# IND83212 register map
Series: Verne; File version: B0
CPU: CM0 r0p1, selectable endian, no MPU, no FPU, 4 interrupt priority bits
Registers are 32-bit, read-write, no defined reset value unless marked. A register's access mark holds for its fields unless they carry their own. Offsets are from the block's base; [hi:lo] are bit positions.

## IOCTRLA — I/O configuration and DFT pin control
Base 0x50011000; register names take the prefix IOCTRLA_
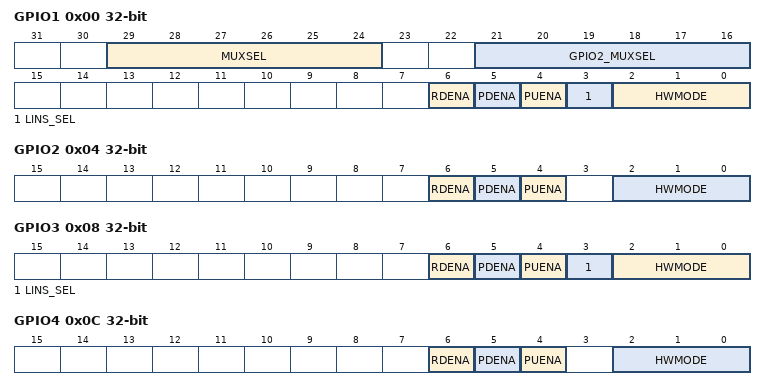
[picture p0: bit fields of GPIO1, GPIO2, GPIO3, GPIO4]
0x00 GPIO1 — GPIO Pin 1 Control
  [29:24] MUXSEL — GPIO1_MUXSEL:Selects debug signal to be output on gpio1. 0x0: PMUA (Power Management Unit Asic) QACK 0x1: PMUA (Power Management Unit Asic) Wakeup signal 0x2: PMUA (Power Management Unit Asic) snowflake 0x3: LIN Slave Output of 1st Stage Glitch Filter 0x4: LIN Slave Output of 2nd Stage Glitch Filter 0x5: LIN Slave Output of 3rd Stage Glitch Filter 0x6: LIN Slave PHY Output Rxd 0x7: LIN Slave PHY Input Txd 0x8: CRGA (Clock Reset Generation Asic) (scan_test_mode | lf_rc_clk) 0x9: CRGA (Clock Reset Generation Asic) (scan_test_mode | hf_rc_clk) 0xa: CRGA (Clock Reset Generation Asic) (scan_test_mode | lf_rc_sts) 0xb: CRGA (Clock Reset Generation Asic) (scan_test_mode | hf_rc_sts) 0xc: CRGA (Clock Reset Generation Asic) (scan_test_mode | clk_sys_gated) 0xd: CRGA (Clock Reset Generation Asic) (a_por_n) 0xe: CRGA (Clock Reset Generation Asic) (bor_3v3_n) 0xf: CRGA (Clock Reset Generation Asic) (ovtemp_flag) 0x10: CRGA (Clock Reset Generation Asic) (bor_1v5_n) 0x11: CRGA (Clock Reset Generation Asic) (wdt_bark) 0x12: ADC controller clk adc_clk_in 0x22: LIN Slave Input of Core rxd 0x23: LIN Slave Output of Core txd 0x24: BOR CONTROL STATE MACHINE state[0] 0x25: BOR CONTROL STATE MACHINE state[1] 0x26: BOR CONTROL STATE MACHINE bor_bias_ena 0x27: BOR CONTROL STATE MACHINE bor_bias_ena_l 0x28: BOR CONTROL STATE MACHINE pmua_bor_bias_ena 0x29: BOR CONTROL STATE MACHINE hf_clk_allowed 0x2a: BOR CONTROL STATE MACHINE hf_active 0x2b: BOR CONTROL STATE MACHINE pmua_bor_arm_sync 0x2c: BATTERY VOLTAGE MONITOR vbat_low 0x2d: BATTERY VOLTAGE MONITOR vbat_high 0x2e: BATTERY VOLTAGE MONITOR vbat_low_flag 0x2f: BATTERY VOLTAGE MONITOR vbat_high_flag 0x30: BATTERY VOLTAGE MONITOR vbat_low_dbnc 0x31: BATTERY VOLTAGE MONITOR vbat_high_dbnc
  [21:16] GPIO2_MUXSEL — Selects debug signal to be output on gpio2. Refer to GPIO1_MUXSEL for signal selection
  [6] RDENA — read enable. 0x0: Disable Read path on the GPIO 0x1: Enable Read path on the GPIO
  [5] PDENA — pulldown enable. 0x0: Disable 100K Ohm Pull Down 0x1: Enable 100K Ohm Pull Down
  [4] PUENA — pullup enable (active-low). 0x0: Enable 100K Ohm Pull Up 0x1: Disable 100K Ohm Pull Up
  [3] LINS_SEL — LINS Connection Select. 0x0: LINS RXD External input Mode. 0x1: Single wire mode, LINS RXD/LINS TXD, Open-drain output.
  [2:0] HWMODE — hardware mode. 0x0: GPIO Mode. 'GPIO Barium' reads and writes data to the GPIO. Output Enable is controlled by GPIO Barium via the direction bit. Read Enable, Pull-Up, and Pull-Down are controlled by GPIO register in IOCTRLA. 0x1: PWM Mode. 'PWM Barium' writes data to the GPIO. 0x2: Testmux Mode. 'Digital Testmux' writes data to the GPIO. DEBUG Access must be enabled in the system control block to allow testmux outputs. 0x3: GPIO1_LINS_SEL=0 : LINS RXD; GPIO1_LINS_SEL=1 : Single wire mode, LINS RXD/LINS TXD, Open-drain output. 0x4: Monitor 1st Stage input of LINS RX Glitch filter. 0x5: Monitor 1st Stage output of LINS RX Glitch filter. 0x6: Monitor 2nd Stage output of LINS RX Glitch filter. 0x7: Monitor 3rd Stage output of LINS RX Glitch filter.
0x04 GPIO2 — GPIO Pin 2 Control
  [6] RDENA — read enable. 0x0: Disable Read path on the GPIO 0x1: Enable Read path on the GPIO
  [5] PDENA — pulldown enable. 0x0: Disable 100K Ohm Pull Down 0x1: Enable 100K Ohm Pull Down
  [4] PUENA — pullup enable (active-low). 0x0: Enable 100K Ohm Pull Up 0x1: Disable 100K Ohm Pull Up
  [2:0] HWMODE — hardware mode. 0x0: GPIO Mode. 'GPIO Barium' reads and writes data to the GPIO. Output Enable is controlled by GPIO Barium via the direction bit. Read Enable, Pull-Up, and Pull-Down are controlled by GPIO register in IOCTRLA. 0x1: PWM Mode. 'PWM Barium' writes data to the GPIO. 0x2: LINS PHY TXD Drive Mode. GPIO input connects to LINS PHY TXD. DEBUG Access must be enabled in the system control block to drive LINS PHY TXD outputs. 0x3: LINS Core TXD Monitor. 0x4: Testmux Mode. 'Digital Testmux' writes data to the GPIO. DEBUG Access must be enabled in the system control block to allow testmux outputs. 0x5: Monitor 1st Stage output of LINS RX Glitch filter. 0x6: Monitor 2nd Stage output of LINS RX Glitch filter. 0x7: Monitor 3rd Stage output of LINS RX Glitch filter.
0x08 GPIO3 — GPIO Pin 3 Control
  [6] RDENA — read enable. 0x0: Disable Read path on the GPIO 0x1: Enable Read path on the GPIO
  [5] PDENA — pulldown enable. 0x0: Disable 100K Ohm Pull Down 0x1: Enable 100K Ohm Pull Down
  [4] PUENA — pullup enable (active-low). 0x0: Enable 100K Ohm Pull Up 0x1: Disable 100K Ohm Pull Up
  [3] LINS_SEL — LINS Connection Select. 0x0: LINS RXD External input Mode. 0x1: Single wire mode, LINS RXD/LINS TXD, Open-drain output.
  [2:0] HWMODE — hardware mode. 0x0: GPIO Mode. 'GPIO Barium' reads and writes data to the GPIO. Output Enable is controlled by GPIO Barium via the direction bit. Read Enable, Pull-Up, and Pull-Down are controlled by GPIO register in IOCTRLA. 0x1: PWM Mode. 'PWM Barium' writes data to the GPIO. 0x2: LINS RXD which is input of lins_core connects to GPIO output. 0x3: LINS_SEL=0 : LINS RXD; LINS_SEL=1 : Single wire mode, LINS RXD/LINS TXD, Open-drain output. 0x4: Monitor 1st Stage input of LINS RX Glitch filter. 0x5: Monitor 1st Stage output of LINS RX Glitch filter. 0x6: Monitor 2nd Stage output of LINS RX Glitch filter. 0x7: Monitor 3rd Stage output of LINS RX Glitch filter.
0x0C GPIO4 — GPIO Pin 4 Control
  [6] RDENA — read enable. 0x0: Disable Read path on the GPIO 0x1: Enable Read path on the GPIO
  [5] PDENA — pulldown enable. 0x0: Disable 100K Ohm Pull Down 0x1: Enable 100K Ohm Pull Down
  [4] PUENA — pullup enable (active-low). 0x0: Enable 100K Ohm Pull Up 0x1: Disable 100K Ohm Pull Up
  [2:0] HWMODE — hardware mode. 0x0: GPIO Mode. 'GPIO Barium' reads and writes data to the GPIO. Output Enable is controlled by GPIO Barium via the direction bit. Read Enable, Pull-Up, and Pull-Down are controlled by GPIO register in IOCTRLA. 0x1: PWM Mode. 'PWM Barium' writes data to the GPIO. 0x2: Testmux Mode. GPIO input connects to LINS TXD. 0x3: LINS CORE TXD Monitor 0x4: Monitor 1st Stage input of LINS RX Glitch filter. 0x5: Monitor 1st Stage output of LINS RX Glitch filter. 0x6: Monitor 2nd Stage output of LINS RX Glitch filter. 0x7: Monitor 3rd Stage output of LINS RX Glitch filter.
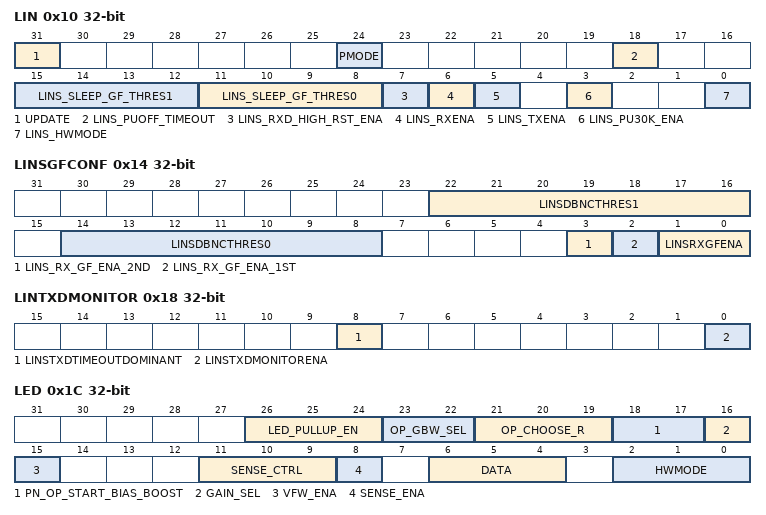
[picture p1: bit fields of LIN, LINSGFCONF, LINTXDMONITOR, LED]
0x10 LIN — LIN Pin Control
  [31] UPDATE dual — LIN Configure Update. Set to update the Configurations to PRE5V domains. NOTE: DO NOT change the CTRL register when it is high, which indicates there is an update in progress, It gets cleared by the core when the current update is done
  [24] PMODE — LIN Power Mode. Control LINS power state in hibernate mode. 0x0: Regardless of the related enable bits, LIN TX analog parts will be shut-down in hibernate mode, unless any LIN dominant signal is detected. 0x1: LIN TX analog parts are still controlled by theirs corresponding enable bits.
  [18] LINS_PUOFF_TIMEOUT — LINS Pullup Disable in dominant TimeOut condition. Set to disable LINS 30K pullup in case that lin bus is shorted to ground(Bus idle dominant timeout is detected) for saving power. LINS Pullup will be recovered automatically if bus idle dominant timeout is released by any bus activity. Only reset by power-on sequence. NOTE: The write operation of this register takes effect by PMUA_SFRS->CTRL.UPDATE
  [15:12] LINS_SLEEP_GF_THRES1 — LINS RXD glitch filter threshold for 0 to 1, detect '1' width of (T_clk_lf*resetvalue = 4us*3 = 12[us], NOTE: The write operation of this register takes effect by configuring SYSCTRLA_SFRS->TRIM_ACCESS_KEY.TRIM_ACCESS_KEY, FILT_ACCESS.FILT_UNLOCK and IOCTRLA_SFRS->LIN.UPDATE
  [11:8] LINS_SLEEP_GF_THRES0 — LINS RXD glitch filter threshold for 1 to 0, detect '0' width of (T_clk_lf*resetvalue = 4us*3 = 12[us], NOTE: The write operation of this register takes effect by configuring SYSCTRLA_SFRS->TRIM_ACCESS_KEY.TRIM_ACCESS_KEY, FILT_ACCESS.FILT_UNLOCK and IOCTRLA_SFRS->LIN.UPDATE
  [7] LINS_RXD_HIGH_RST_ENA — Enable signal that LINs RXD glitch filter at sleep mode is asynchronous reset by high of LINs_RXD. NOTE: The write operation of this register takes effect by configuring SYSCTRLA_SFRS->TRIM_ACCESS_KEY.TRIM_ACCESS_KEY, FILT_ACCESS.FILT_UNLOCK and IOCTRLA_SFRS->LIN.UPDATE
  [6] LINS_RXENA — LIN receive enable. NOTE: The write operation of this register takes effect by IOCTRLA_SFRS->LIN.UPDATE
  [5] LINS_TXENA — LIN transmit enable.
  [3] LINS_PU30K_ENA — LIN 30K pullup enable.
  [0] LINS_HWMODE — LIN Slave hardware mode. 0x0: Hardware Mode Disabled. GPIO2 writes/reads the LIN I/O pin. 0x1: Hardware Mode Enabled. LIN peripheral writes/reads the LIN I/O pin.
0x14 LINSGFCONF — LINS Glitch Filter Configuration in active mode
  [22:16] LINSDBNCTHRES1 — 3rd Stage LINS Debounce Threshold for 0 to 1. 3rd Stage LINS Debounce Threshold for 0 to 1, detect '1' width of (T_clksys*resetvalue = 62.5ns*40 = 2.5[us]. NOTE: The write operation of this register takes effect by configuring SYSCTRLA_SFRS->TRIM_ACCESS_KEY.TRIM_ACCESS_KEY, FILT_ACCESS.FILT_UNLOCK
  [14:8] LINSDBNCTHRES0 — 3rd Stage LINS Debounce Threshold for 1 to 0. 3rd Stage LINS Debounce Threshold for 1 to 0, detect '0' width of (T_clksys*resetvalue = 62.5ns*40 = 2.5[us]. NOTE: The write operation of this register takes effect by configuring SYSCTRLA_SFRS->TRIM_ACCESS_KEY.TRIM_ACCESS_KEY, FILT_ACCESS.FILT_UNLOCK
  [3] LINS_RX_GF_ENA_2ND — LINS RXD 2nd Glitch Filter enables. Enable LINS Glitch Filter 2nd stage. NOTE: The write operation of this register takes effect by configuring SYSCTRLA_SFRS->TRIM_ACCESS_KEY.TRIM_ACCESS_KEY, FILT_ACCESS.FILT_UNLOCK
  [2] LINS_RX_GF_ENA_1ST — LINS RXD 1st Glitch Filter enables. Enable LINS Glitch Filter 1st stage. NOTE: The write operation of this register takes effect by configuring SYSCTRLA_SFRS->TRIM_ACCESS_KEY.TRIM_ACCESS_KEY, FILT_ACCESS.FILT_UNLOCK
  [1:0] LINSRXGFENA — LINS RXD Glitch Filter enables. Bit0: Enable LINS Glitch Filter 3rd stage; Bit1: Enable LINS Glitch Filter for Sleep Mode. NOTE: The write operation of this register takes effect by configuring SYSCTRLA_SFRS->TRIM_ACCESS_KEY.TRIM_ACCESS_KEY, FILT_ACCESS.FILT_UNLOCK
0x18 LINTXDMONITOR — LIN TXD Dominant Timeout
  [8] LINSTXDTIMEOUTDOMINANT ro — Tx Dominant Timeout. The bit is set by LINS TxD monitor if LINS's TxD is stuck at dominant output for 64ms. A dominant to recessive transition of the TxD will clear this bit. LIN's TX will be disabled automatically when this bit is set.
  [0] LINSTXDMONITORENA — LINS TxD Monitor enable.
0x1C LED — LED Pin Control
  [26:24] LED_PULLUP_EN — LED PULLUP ENABLE. LED PAD Pullup enable, ONE HOT code. 0x1: LED0 PAD pullup to PRE5V through a diode and a 50K resistor 0x2: LED1 PAD pullup to PRE5V through a diode and a 50K resistor 0x4: LED2 PAD pullup to PRE5V through a diode and a 50K resistor
  [23:22] OP_GBW_SEL — LED SENSE OP GBW SEL. PN detect fully differential Op GBW choose 00: 3M 01: 5M 10: 8M 11: 10M
  [21:19] OP_CHOOSE_R — LED SENSE OP CHOOSE R. choose nulling resistor to do frequency compensation. Which denpends on the bandwidth of the OP. R<2:0> R GBW<1:0>(CL=3pF) 000 0.5K 11(10M) 001 2.5K 10(8M) 01(5M) 010 4.5K 011 6.5K 11(3M) 100 8.5K 101 10.5K 110 12.5K 111 14.5K
  [18:17] PN_OP_START_BIAS_BOOST — PN OP START BIAS BOOST. PN diff OP start bias current 00: 250nA 01: 500nA 10: 750nA 11: 1uA
  [16] GAIN_SEL — LED Sense AFE gain select. V_ADC = (vbat-vled)*GAIN , where V_ADC is voltage to ADC LED channle, and GAIN is selected by GAIN_SEL as following: 0x0: GAIN = 0.533 0x1: GAIN = 0.533/2
  [15] VFW_ENA — LED Forward Voltage Current Enable. Set to enable the independent LED VFW current source(maximum=5mA). When ADC CH2 measurement is active, the LED channel selected by CH2_SEL will be driven by LED_VFW current source.
  [11:9] SENSE_CTRL — LED. LED Sense Control bits for override control/debug.
  [8] SENSE_ENA — LED Forward Voltage Sense Enable. Set to enable LED forward voltage sense module. After setting this bit, it's recommended to wait ~40us before ADC conversion for LED_SENSE to settle down.
  [6:4] DATA — LED Data Out. When the LED hardware mode is disabled, then the data in this register bit is used to drive the LED driver. Each bit controls the corresonding LED Channel respectively.
  [2:0] HWMODE — LED hardware mode. LED Hardware Mode Enable. Each bit controls the corresponding LED Channel respectively. 0x0: Hardware Mode Disabled. LED_DATA register drives the LED Data Output pin. Read is not available on this pin. 0x1: Hardware Mode Enabled. PWM_BARIUM peripheral drives the LED Data Output pin. Read is not available on this pin.
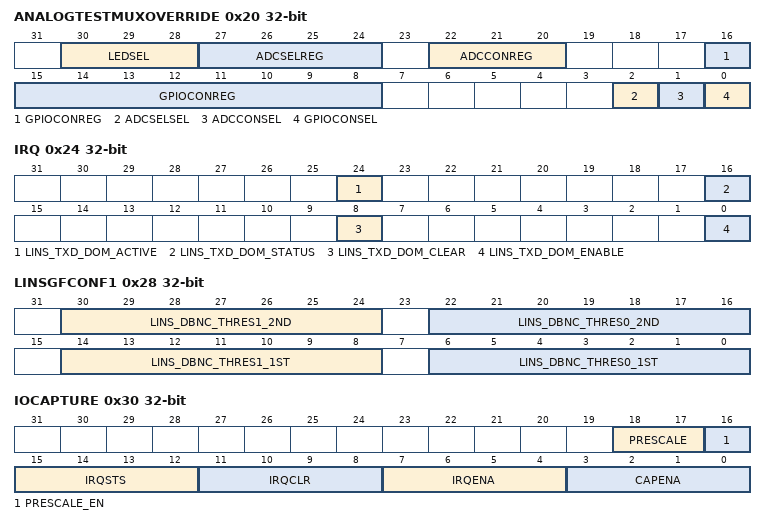
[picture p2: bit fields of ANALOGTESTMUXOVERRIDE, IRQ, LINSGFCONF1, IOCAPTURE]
0x20 ANALOGTESTMUXOVERRIDE — Analog Testmux Override.This register controls the multiplexers for analog signals. The select bit allows firmware to control the corresponding select field (in other words, firmware control). The following table is intended to be a helpful guide in what data should be written to this register in order to connect a source and target together. Note- Care should be taken to write zero to this register between connection changes. This ensures a clean break between selections. Data to write at ANALOG_TESTMUX_OVERRIDE to enable connection Source Description Target Description Data to write to connect Source to Target 3.3V Digital Supply * 1/2 GPIO1 0x0000_0107 1.5V Digital Supply GPIO1 0x0000_0207 VDD_PRE5v * 1/4 GPIO1 0x0000_0407 VBG_1P2V GPIO2 0x0000_0807 VBG_BUF GPIO2 0x0000_1007 VREF_1P1 GPIO2 0x0000_2007 Temperature Sensor GPIO2 0x0000_4007 ADC_REFP GPIO2 0x0000_8007 BOR_REF GPIO2 0x0001_0007
  [30:28] LEDSEL — Firmware Debug Value. 0x1: Enable LED0 analog connection for short to gnd detecting 0x2: Enable LED1 analog connection for short to gnd detecting 0x4: Enable LED2 analog connection for short to gnd detecting
  [27:24] ADCSELREG — Firmware Debug Value. need to be configured TOGETHER WITH GPIO_CON_REG to enable GPIO0/1 PAD output. (ADC_SEL_SEL also need to be set to 1) 0x1: Enable GPIO0 analog connection to ADC 0x2: Enable GPIO1 analog connection to ADC 0x4: Enable GPIO2 analog connection to ADC 0x8: Enable GPIO3 analog connection to ADC
  [22:20] ADCCONREG — Firmware Debug Value. Contains the output value when the ADC_CON_SEL firmware select bit is set 0x1: Select LED0 Forward Voltage for measurement 0x2: Select LED1 Forward Voltage for measurement 0x4: Select LED2 Forward Voltage for measurement
  [16:8] GPIOCONREG — Firmware Debug Value. GPIO test MUX select 0x1: Select VDD3V3*1/2 to GPIO1 0x2: Select VDD1V5 to GPIO1 0x4: Select VDD_PRE5V*1/4 to GPIO1 0x8: Select VBG_1P2V to GPIO2 0x10: Select VBG_BUF to GPIO2 0x20: Select VREF_1P1 to GPIO2 0x40: Select tempsensor to GPIO2 0x80: Select ADC_REFP to GPIO2 0x100: Select BOR_REF from GPIO2, for BOR trig point test
  [2] ADCSELSEL — Hardware/Firmware Select. 0x0: Hardware Controlled. 0x1: ADC_SEL_REG controls output.
  [1] ADCCONSEL — ADC CON SEL. 0x0: Hardware Controlled. 0x1: ADC_CON_REG controls output.
  [0] GPIOCONSEL — Hardware/Firmware Select. 0x0: Hardware Controlled. 0x1: GPIO_CON_REG controls output.
0x24 IRQ — IOCTRLA LINS TXD Dominant Monitor interrupts
  [24] LINS_TXD_DOM_ACTIVE ro — LINS TXD Dominant Monitor interrupt active.
  [16] LINS_TXD_DOM_STATUS ro — LINS TXD Dominant Monitor interrupt status.
  [8] LINS_TXD_DOM_CLEAR wo — LINS TXD Dominant Monitor interrupt clear. Autoclear: includes a synchronous reset signal which clears the register on the cycle following write.
  [0] LINS_TXD_DOM_ENABLE — LINS TXD Dominant Monitor interrupt enable.
0x28 LINSGFCONF1 — LINS Glitch Filter Configuration in active mode
  [30:24] LINS_DBNC_THRES1_2ND — 2nd Stage LINS Debounce Threshold for 0 to 1. 2nd Stage LINS Debounce Threshold for 0 to 1, detect '1' width of (T_clksys*resetvalue = 62.5ns*32 = 2[us]). NOTE: The write operation of this register takes effect by configuring SYSCTRLA_SFRS->TRIM_ACCESS_KEY.TRIM_ACCESS_KEY, FILT_ACCESS.FILT_UNLOCK
  [22:16] LINS_DBNC_THRES0_2ND — 2nd Stage LINS Debounce Threshold for 1 to 0. 2nd Stage LINS Debounce Threshold for 1 to 0, detect '0' width of (T_clksys*resetvalue = 62.5ns*16 = 1[us]). NOTE: The write operation of this register takes effect by configuring SYSCTRLA_SFRS->TRIM_ACCESS_KEY.TRIM_ACCESS_KEY, FILT_ACCESS.FILT_UNLOCK
  [14:8] LINS_DBNC_THRES1_1ST — 1st Stage LINS Debounce Threshold for 0 to 1. 1st Stage LINS Debounce Threshold for 0 to 1, detect '1' width of (T_clksys*resetvalue = 62.5ns*0 = 0[us]). NOTE: The write operation of this register takes effect by configuring SYSCTRLA_SFRS->TRIM_ACCESS_KEY.TRIM_ACCESS_KEY, FILT_ACCESS.FILT_UNLOCK
  [6:0] LINS_DBNC_THRES0_1ST — 1st Stage LINS Debounce Threshold for 1 to 0. 1st Stage LINS Debounce Threshold for 1 to 0, detect '0' width of (T_clksys*resetvalue = 62.5ns*8 = 0.5[us]). NOTE: The write operation of this register takes effect by configuring SYSCTRLA_SFRS->TRIM_ACCESS_KEY.TRIM_ACCESS_KEY, FILT_ACCESS.FILT_UNLOCK
0x2C FILT_ACCESS — Glitch Filter access key
  [31] FILT_UNLOCK — Set Only bit. Write 1 to this bit to un-lock FILT_CODE bits.
0x30 IOCAPTURE — IO capture controller
  [18:17] PRESCALE — prescaler select. 0x0: Divide by 1. 0x1: Divide by 2 0x2: Divide by 4 0x3: Divide by 8
  [16] PRESCALE_EN — prescale enable. prescale enable.
  [15:12] IRQSTS ro — IO capture irq status. io capture irq status.
  [11:8] IRQCLR — IO capture irq clear. clear io capture irq. Autoclear: includes a synchronous reset signal which clears the register on the cycle following write.
  [7:4] IRQENA — IO capture irq enable. enable io capture irq, gpio posedge or io capture counter exceeds the threshold will trigger interrupt.
  [3:0] CAPENA — IO capture enable. enable io capture.
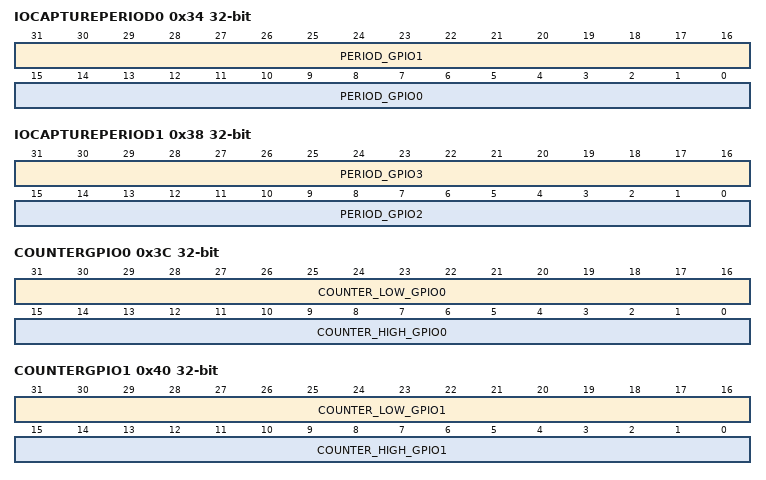
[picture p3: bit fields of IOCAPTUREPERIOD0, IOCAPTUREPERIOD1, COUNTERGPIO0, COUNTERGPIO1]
0x34 IOCAPTUREPERIOD0
  [31:16] PERIOD_GPIO1 — GPIO1 input signal period. GPIO1 input signal period.
  [15:0] PERIOD_GPIO0 — GPIO0 input signal period. GPIO0 input signal period.
0x38 IOCAPTUREPERIOD1
  [31:16] PERIOD_GPIO3 — GPIO3 input signal period. GPIO3 input signal period.
  [15:0] PERIOD_GPIO2 — GPIO2 input signal period. GPIO2 input signal period.
0x3C COUNTERGPIO0
  [31:16] COUNTER_LOW_GPIO0 ro — GPIO0 input low level counter. GPIO0 input low level counter, the low level width is equal to the counter plus 1.
  [15:0] COUNTER_HIGH_GPIO0 ro — GPIO0 input high level counter. GPIO0 input high level counter, the high level width is equal to the counter plus 1.
0x40 COUNTERGPIO1
  [31:16] COUNTER_LOW_GPIO1 ro — GPIO1 input low level counter. GPIO1 input low level counter, the low level width is equal to the counter plus 1.
  [15:0] COUNTER_HIGH_GPIO1 ro — GPIO1 input high level counter. GPIO1 input high level counter, the high level width is equal to the counter plus 1.
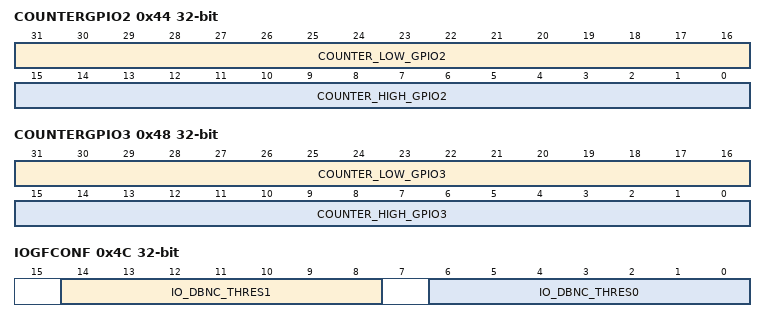
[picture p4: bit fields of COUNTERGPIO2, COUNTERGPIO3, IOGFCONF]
0x44 COUNTERGPIO2
  [31:16] COUNTER_LOW_GPIO2 ro — GPIO2 input low level counter. GPIO0 input low level counter, the low level width is equal to the counter plus 1.
  [15:0] COUNTER_HIGH_GPIO2 ro — GPIO2 input high level counter. GPIO2 input high level counter, the high level width is equal to the counter plus 1.
0x48 COUNTERGPIO3
  [31:16] COUNTER_LOW_GPIO3 ro — GPIO3 input low level counter. GPIO3 input low level counter.
  [15:0] COUNTER_HIGH_GPIO3 ro — GPIO3 input high level counter. GPIO3 input high level counter.
0x4C IOGFCONF — IO capture Glitch Filter Configuration in active mode
  [14:8] IO_DBNC_THRES1 — IO Debounce Threshold for 0 to 1. IO Debounce Threshold for 0 to 1, detect '1' width of (T_clksys*resetvalue = 62.5ns*8 = 0.5[us]). NOTE: The write operation of this register takes effect by configuring SYSCTRLA_SFRS->TRIM_ACCESS_KEY.TRIM_ACCESS_KEY, FILT_ACCESS.FILT_UNLOCK
  [6:0] IO_DBNC_THRES0 — IO Debounce Threshold for 1 to 0. IO Debounce Threshold for 1 to 0, detect '0' width of (T_clksys*resetvalue = 62.5ns*8 = 0.5[us]). NOTE: The write operation of this register takes effect by configuring SYSCTRLA_SFRS->TRIM_ACCESS_KEY.TRIM_ACCESS_KEY, FILT_ACCESS.FILT_UNLOCK
